# LPC11Exx register map
File version: 5
CPU: CM0 r0p0, little endian, no MPU, no FPU, 0x2 interrupt priority bits, 0x0 interrupts
Registers are 32-bit, read-write, reset 0x0 unless marked. A register's access mark holds for its fields unless they carry their own. Offsets are from the block's base; [hi:lo] are bit positions; {n}, {i} and the like mark numbered series.

## GPIO_PIN_INT — Product name title=UM10462 Chapter title=LPC11U1x GPIO Modification date=3/17/2011 Major revision=0 Minor revision=3
Base 0x4004C000
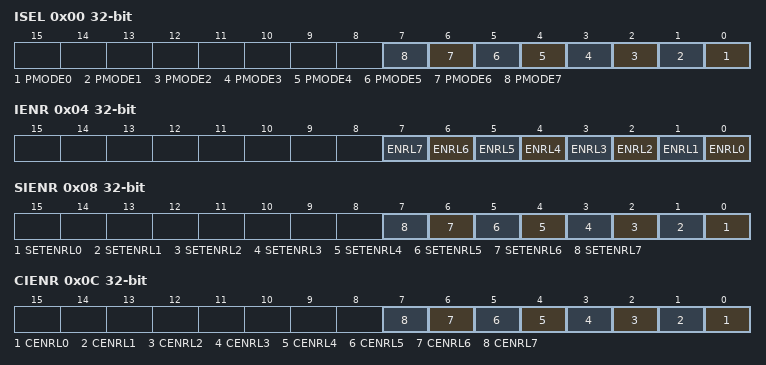
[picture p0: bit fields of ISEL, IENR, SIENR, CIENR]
0x00 ISEL — Pin Interrupt Mode register
  [n] PMODE{n} (n=0..7) — Selects the interrupt mode for each pin interrupt. Bit n configures the pin interrupt selected in PINTSELn. 0 = Edge sensitive 1 = Level sensitive
0x04 IENR — Pin Interrupt Enable (Rising) register
  [n] ENRL{n} (n=0..7) — Enables the rising edge or level interrupt for each pin interrupt. Bit n configures the pin interrupt selected in PINTSELn. 0 = Disable rising edge or level interrupt. 1 = Enable rising edge or level interrupt.
0x08 SIENR wo reset not defined — Set Pin Interrupt Enable (Rising) register
  [n] SETENRL{n} (n=0..7) — Ones written to this address set bits in the PINTEN_R, thus enabling interrupts. Bit n sets bit n in the PINTEN_R register. 0 = No operation. 1 = Enable rising edge or level interrupt.
0x0C CIENR wo reset not defined — Clear Pin Interrupt Enable (Rising) register
  [n] CENRL{n} (n=0..7) — Ones written to this address clear bits in the IENR, thus disabling the interrupts. Bit n clears bit n in the IENR register. 0 = No operation. 1 = Disable rising edge or level interrupt.
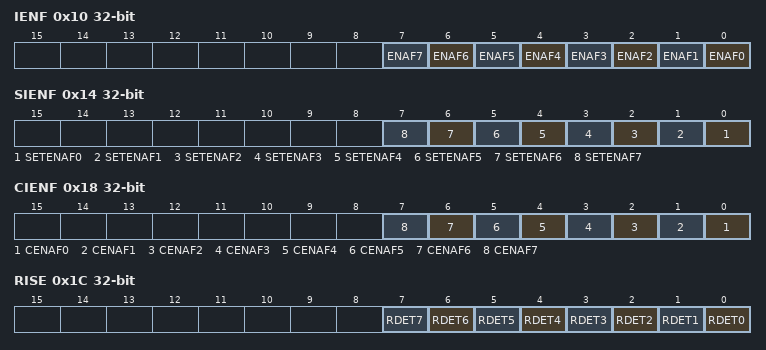
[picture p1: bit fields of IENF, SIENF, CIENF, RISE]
0x10 IENF — Pin Interrupt Enable Falling Edge / Active Level register
  [n] ENAF{n} (n=0..7) — Enables the falling edge or configures the active level interrupt for each pin interrupt. Bit n configures the pin interrupt selected in PINTSELn. 0 = Disable falling edge interrupt or set active interrupt level LOW. 1 = Enable falling edge interrupt enabled or set active interrupt level HIGH.
0x14 SIENF wo reset not defined — Set Pin Interrupt Enable Falling Edge / Active Level register
  [n] SETENAF{n} (n=0..7) — Ones written to this address set bits in the IENF, thus enabling interrupts. Bit n sets bit n in the IENF register. 0 = No operation. 1 = Select HIGH-active interrupt or enable falling edge interrupt.
0x18 CIENF wo reset not defined — Clear Pin Interrupt Enable Falling Edge / Active Level address
  [n] CENAF{n} (n=0..7) — Ones written to this address clears bits in the IENF, thus disabling interrupts. Bit n clears bit n in the IENF register. 0 = No operation. 1 = LOW-active interrupt selected or falling edge interrupt disabled.
0x1C RISE — Pin Interrupt Rising Edge register
  [n] RDET{n} (n=0..7) — Rising edge detect. Bit n detects the rising edge of the pin selected in PINTSELn. Read 0: No rising edge has been detected on this pin since Reset or the last time a one was written to this bit. Write 0: no operation. Read 1: a rising edge has been detected since Reset or the last time a one was written to this bit. Write 1: clear rising edge detection for this pin.
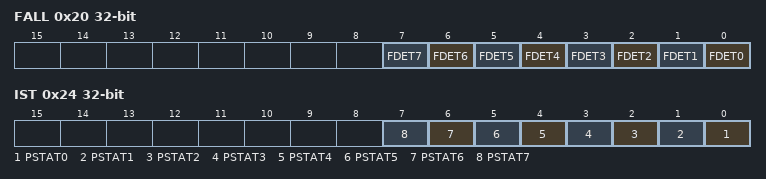
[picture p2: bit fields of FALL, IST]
0x20 FALL — Pin Interrupt Falling Edge register
  [n] FDET{n} (n=0..7) — Falling edge detect. Bit n detects the falling edge of the pin selected in PINTSELn. Read 0: No falling edge has been detected on this pin since Reset or the last time a one was written to this bit. Write 0: no operation. Read 1: a falling edge has been detected since Reset or the last time a one was written to this bit. Write 1: clear falling edge detection for this pin.
0x24 IST — Pin Interrupt Status register
  [n] PSTAT{n} (n=0..7) — Pin interrupt status. Bit n returns the status, clears the edge interrupt, or inverts the active level of the pin selected in PINTSELn. Read 0: interrupt is not being requested for this interrupt pin. Write 0: no operation. Read 1: interrupt is being requested for this interrupt pin. Write 1 (edge-sensitive): clear rising- and falling-edge detection for this pin. Write 1 (level-sensitive): switch the active level for this pin (in the PINTENT_F register).
